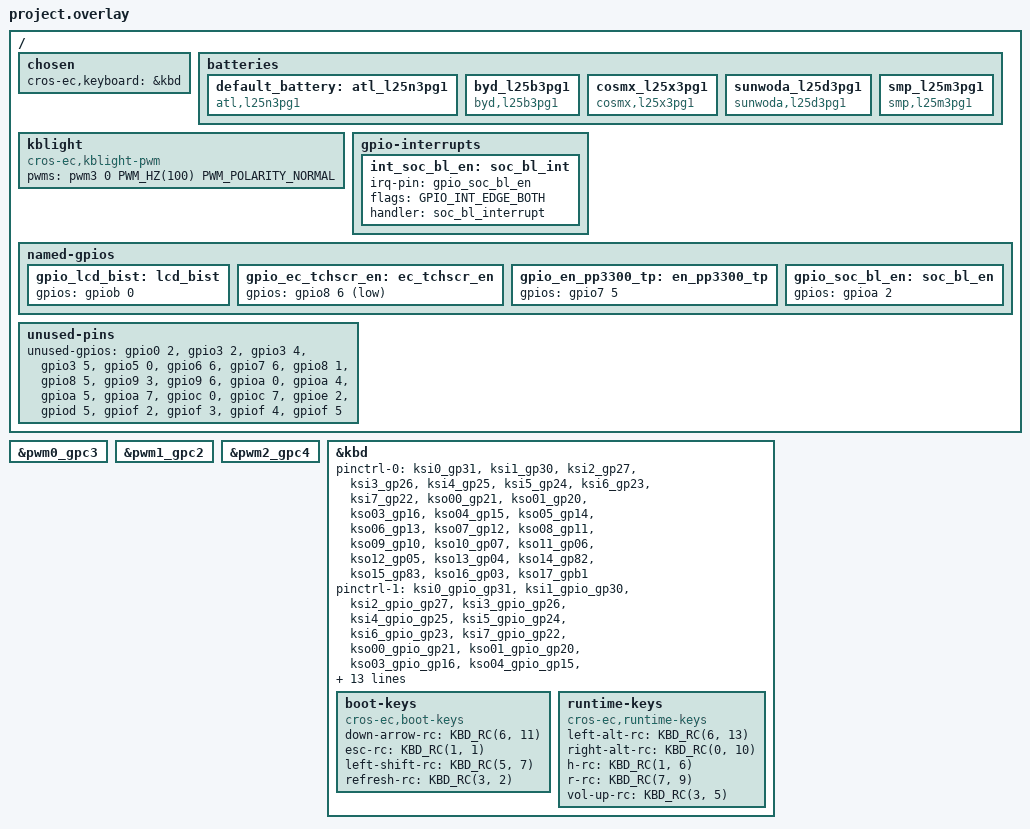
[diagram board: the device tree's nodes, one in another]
/* Copyright 2025 The ChromiumOS Authors
 * Use of this source code is governed by a BSD-style license that can be
 * found in the LICENSE file.
 */

#include <cros/cbi_flash.dtsi>
#include "../npcx_generated.dtsi"
#include "../interrupts.dtsi"
#include "../npcx_common.dtsi"
#include "../npcx_default_gpio_pinctrl.dtsi"
#include "../npcx_keyboard.dtsi"
#include "../npcx_overlay.dtsi"
#include "../npcx_usbc.dtsi"
#include "../power_signal.dtsi"
#include "../usba.dtsi"
#include "cbi.dtsi"
#include "led_pins.dtsi"
#include "led_policy.dtsi"
#include "temp_sensors.dtsi"

/ {
	chosen {
		cros-ec,keyboard = &kbd;
	};
	batteries {
		default_battery: atl_l25n3pg1 {
			compatible = "atl,l25n3pg1", "battery-smart";
		};
		byd_l25b3pg1 {
			compatible = "byd,l25b3pg1", "battery-smart";
		};
		cosmx_l25x3pg1 {
			compatible = "cosmx,l25x3pg1", "battery-smart";
		};
		sunwoda_l25d3pg1 {
			compatible = "sunwoda,l25d3pg1", "battery-smart";
		};
		smp_l25m3pg1 {
			compatible = "smp,l25m3pg1", "battery-smart";
		};
	};

	kblight {
		compatible = "cros-ec,kblight-pwm";
		pwms = <&pwm3 0 PWM_HZ(100) PWM_POLARITY_NORMAL>;
	};

	gpio-interrupts {
		/delete-node/ lid-accel;
		/delete-node/ ec-imu;
		/delete-node/ tablet_mode;
		/delete-node/ volume-up;
		/delete-node/ volume-down;

		int_soc_bl_en: soc_bl_int{
			irq-pin = <&gpio_soc_bl_en>;
			flags = <GPIO_INT_EDGE_BOTH>;
			handler = "soc_bl_interrupt";
		};
	};

	named-gpios {
		/delete-node/ en_pp5000_z1;
		/delete-node/ ec_voldn_btn_odl;
		/delete-node/ ec_volup_btn_odl;

		gpio_lcd_bist: lcd_bist {
			gpios = <&gpiob 0 (GPIO_OUTPUT | GPIO_ACTIVE_HIGH | GPIO_OUTPUT_INIT_LOW)>;
		};
		gpio_ec_tchscr_en: ec_tchscr_en {
			gpios = <&gpio8 6 (GPIO_OUTPUT | GPIO_ACTIVE_LOW)>;
		};
		gpio_en_pp3300_tp: en_pp3300_tp {
			gpios = <&gpio7 5 (GPIO_OUTPUT | GPIO_ACTIVE_HIGH | GPIO_OUTPUT_INIT_LOW)>;
		};
		gpio_soc_bl_en: soc_bl_en {
			gpios = <&gpioa 2 (GPIO_INPUT | GPIO_PULL_UP)>;
		};
	};

	unused-pins {
		unused-gpios =
			<&gpio0 2 0>,
			<&gpio3 2 0>,
			<&gpio3 4 0>, /* Reserved for 5V_PWR_MODE */
			<&gpio3 5 0>,
			<&gpio5 0 0>, /* Reserved for PP1800_TCHPAD_EN */
			<&gpio6 6 0>,
			<&gpio7 6 0>,
			<&gpio8 1 0>,
			<&gpio8 5 0>,
			<&gpio9 3 0>,
			<&gpio9 6 0>,
			<&gpioa 0 0>,
			<&gpioa 4 0>,
			<&gpioa 5 0>, /* Reserved for eSIM erasure */
			<&gpioa 7 0>,
			<&gpioc 0 0>,
			<&gpioc 7 0>,
			<&gpioe 2 0>,
			<&gpiod 5 0>,
			<&gpiof 2 0>,
			<&gpiof 3 0>,
			<&gpiof 4 0>,
			<&gpiof 5 0>;
	};
};

&pwm0_gpc3 {
	/delete-property/ drive-open-drain;
};

&pwm1_gpc2 {
	/delete-property/ drive-open-drain;
};

&pwm2_gpc4 {
	/delete-property/ drive-open-drain;
};

&kbd {
	status = "okay";
	pinctrl-0 = <
		&ksi0_gp31
		&ksi1_gp30
		&ksi2_gp27
		&ksi3_gp26
		&ksi4_gp25
		&ksi5_gp24
		&ksi6_gp23
		&ksi7_gp22
		&kso00_gp21
		&kso01_gp20
		&kso03_gp16
		&kso04_gp15
		&kso05_gp14
		&kso06_gp13
		&kso07_gp12
		&kso08_gp11
		&kso09_gp10
		&kso10_gp07
		&kso11_gp06
		&kso12_gp05
		&kso13_gp04
		&kso14_gp82
		&kso15_gp83
		&kso16_gp03
		&kso17_gpb1
	>;
	        pinctrl-1 = <
                &ksi0_gpio_gp31
                &ksi1_gpio_gp30
                &ksi2_gpio_gp27
                &ksi3_gpio_gp26
                &ksi4_gpio_gp25
                &ksi5_gpio_gp24
                &ksi6_gpio_gp23
                &ksi7_gpio_gp22
                &kso00_gpio_gp21
                &kso01_gpio_gp20
                &kso03_gpio_gp16
                &kso04_gpio_gp15
                &kso05_gpio_gp14
                &kso06_gpio_gp13
                &kso07_gpio_gp12
                &kso08_gpio_gp11
                &kso09_gpio_gp10
                &kso10_gpio_gp07
                &kso11_gpio_gp06
                &kso12_gpio_gp05
                &kso13_gpio_gp04
                &kso14_gpio_gp82
                &kso15_gpio_gp83
                &kso16_gpio_gp03
                &kso17_gpio_gpb1
        >;
        pinctrl-names = "default", "sleep";
	actual-key-mask = <
		0x08    /* C0 */
		0xff    /* C1 */
		0xff    /* C2 */
		0xff    /* C3 */
		0xff    /* C4 */
		0xff    /* C5 */
		0xff    /* C6 */
		0xa0    /* C7 */
		0xff    /* C8 */
		0xff    /* C9 */
		0x01    /* C10 */
		0xff    /* C11 */
		0xcf    /* C12 */
		0x40    /* C13 */
		0x0a    /* C14 */
		0x40    /* C15 */
		0x01    /* C16 */
		0xc4    /* C17 */
	>;
	row-size = <8>;
	col-size = <18>;
	debounce-down-ms = <20>;
	debounce-up-ms = <20>;

	boot-keys {
		compatible = "cros-ec,boot-keys";
		down-arrow-rc = <KBD_RC(6, 11)>;
		esc-rc = <KBD_RC(1, 1)>;
		left-shift-rc = <KBD_RC(5, 7)>;
		refresh-rc = <KBD_RC(3, 2)>;
	};

	runtime-keys {
		compatible = "cros-ec,runtime-keys";
		left-alt-rc = <KBD_RC(6, 13)>;
		right-alt-rc = <KBD_RC(0, 10)>;
		h-rc = <KBD_RC(1, 6)>;
		r-rc = <KBD_RC(7, 9)>;
		vol-up-rc = <KBD_RC(3, 5)>;
	};

};
